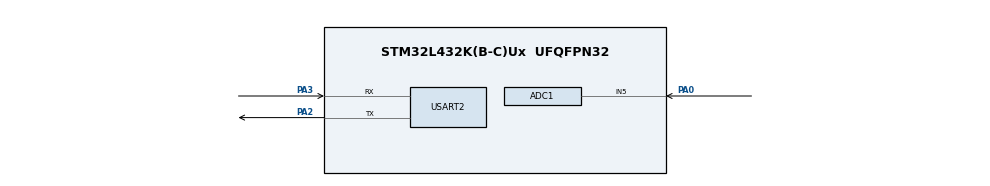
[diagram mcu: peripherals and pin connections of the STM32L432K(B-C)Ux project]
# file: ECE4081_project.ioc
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ADC1.Channel-0\#ChannelRegularConversion=ADC_CHANNEL_5
ADC1.NbrOfConversionFlag=1
ADC1.OffsetNumber-0\#ChannelRegularConversion=ADC_OFFSET_NONE
ADC1.Rank-0\#ChannelRegularConversion=1
ADC1.SamplingTime-0\#ChannelRegularConversion=ADC_SAMPLETIME_2CYCLES_5
ADC1.master=1
Mcu.Family=STM32L4
Mcu.Name=STM32L432K(B-C)Ux
Mcu.Package=UFQFPN32
NVIC.PriorityGroup=NVIC_PRIORITYGROUP_4
NVIC.TIM6_DAC_IRQn=true\:0\:0\:false\:false\:true\:true\:true\:true
PA0.Signal=ADCx_IN5
PA13\ (JTMS-SWDIO).Mode=Serial_Wire
PA13\ (JTMS-SWDIO).Signal=SYS_JTMS-SWDIO
PA14\ (JTCK-SWCLK).Mode=Serial_Wire
PA14\ (JTCK-SWCLK).Signal=SYS_JTCK-SWCLK
PA2.Mode=Asynchronous
PA2.Signal=USART2_TX
PA3.Mode=Asynchronous
PA3.Signal=USART2_RX
ProjectManager.HeapSize=0x200
ProjectManager.StackSize=0x400
ProjectManager.TargetToolchain=STM32CubeIDE
RCC.ADCFreq_Value=32000000
RCC.HSE_VALUE=8000000
RCC.HSI48_VALUE=48000000
RCC.HSI_VALUE=16000000
RCC.LSE_VALUE=32768
RCC.MSI_VALUE=4000000
RCC.PLLSAI1N=16
RCC.USBFreq_Value=32000000
RCC.VCOOutputFreq_Value=32000000
SH.ADCx_IN5.0=ADC1_IN5,IN5-Single-Ended
TIM6.Period=999
TIM6.Prescaler=3
USART2.VirtualMode-Asynchronous=VM_ASYNC
VP_TIM6_VS_ClockSourceINT.Mode=Enable_Timer
board=custom

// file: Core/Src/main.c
/* USER CODE BEGIN Header */
/**
  ******************************************************************************
  * @file           : main.c
  * @brief          : Main program body
  ******************************************************************************
  * @attention
  *
  * Copyright (c) 2026 STMicroelectronics.
  * All rights reserved.
  *
  * This software is licensed under terms that can be found in the LICENSE file
  * in the root directory of this software component.
  * If no LICENSE file comes with this software, it is provided AS-IS.
  *
  ******************************************************************************
  */
/* USER CODE END Header */
#include "main.h"
#include <stdio.h>

ADC_HandleTypeDef hadc1;

TIM_HandleTypeDef htim6;

UART_HandleTypeDef huart2;

/* USER CODE BEGIN PV */
#define SAMPLE_BUFFER_SIZE 256

volatile uint16_t sample_buffer[SAMPLE_BUFFER_SIZE];

volatile uint16_t write_index = 0;
volatile uint16_t read_index = 0;

volatile uint32_t dropped_samples = 0;

char msg[32];
/* USER CODE END PV */

void SystemClock_Config(void);
static void MX_GPIO_Init(void);
static void MX_ADC1_Init(void);
static void MX_USART2_UART_Init(void);
static void MX_TIM6_Init(void);

int main(void)
{

  /* MCU Configuration--------------------------------------------------------*/

  /* Reset of all peripherals, Initializes the Flash interface and the Systick. */
  HAL_Init();

  /* Configure the system clock */
  SystemClock_Config();

  /* Initialize all configured peripherals */
  MX_GPIO_Init();
  MX_ADC1_Init();
  MX_USART2_UART_Init();
  MX_TIM6_Init();
  /* USER CODE BEGIN 2 */
  HAL_ADCEx_Calibration_Start(
      &hadc1,
      ADC_SINGLE_ENDED
  );

  HAL_TIM_Base_Start_IT(
      &htim6
  );
  /* USER CODE END 2 */

  /* Infinite loop */
  while (1)
  {
	  if (read_index != write_index)
	      {
	          uint16_t adc_value =
	              sample_buffer[read_index];

	          read_index =
	              (read_index + 1)
	              % SAMPLE_BUFFER_SIZE;

	          int len = sprintf(
	              msg,
	              "%u\r\n",
	              adc_value
	          );

	          HAL_UART_Transmit(
	              &huart2,
	              (uint8_t *)msg,
	              len,
	              10
	          );
	      }
  }
}

void SystemClock_Config(void)
{
  RCC_OscInitTypeDef RCC_OscInitStruct = {0};
  RCC_ClkInitTypeDef RCC_ClkInitStruct = {0};

  /** Configure the main internal regulator output voltage
  */
  if (HAL_PWREx_ControlVoltageScaling(PWR_REGULATOR_VOLTAGE_SCALE1) != HAL_OK)
  {
    Error_Handler();
  }

  /** Initializes the RCC Oscillators according to the specified parameters
  * in the RCC_OscInitTypeDef structure.
  */
  RCC_OscInitStruct.OscillatorType = RCC_OSCILLATORTYPE_MSI;
  RCC_OscInitStruct.MSIState = RCC_MSI_ON;
  RCC_OscInitStruct.MSICalibrationValue = 0;
  RCC_OscInitStruct.MSIClockRange = RCC_MSIRANGE_6;
  RCC_OscInitStruct.PLL.PLLState = RCC_PLL_NONE;
  if (HAL_RCC_OscConfig(&RCC_OscInitStruct) != HAL_OK)
  {
    Error_Handler();
  }

  /** Initializes the CPU, AHB and APB buses clocks
  */
  RCC_ClkInitStruct.ClockType = RCC_CLOCKTYPE_HCLK|RCC_CLOCKTYPE_SYSCLK
                              |RCC_CLOCKTYPE_PCLK1|RCC_CLOCKTYPE_PCLK2;
  RCC_ClkInitStruct.SYSCLKSource = RCC_SYSCLKSOURCE_MSI;
  RCC_ClkInitStruct.AHBCLKDivider = RCC_SYSCLK_DIV1;
  RCC_ClkInitStruct.APB1CLKDivider = RCC_HCLK_DIV1;
  RCC_ClkInitStruct.APB2CLKDivider = RCC_HCLK_DIV1;

  if (HAL_RCC_ClockConfig(&RCC_ClkInitStruct, FLASH_LATENCY_0) != HAL_OK)
  {
    Error_Handler();
  }
}

static void MX_ADC1_Init(void)
{

  ADC_ChannelConfTypeDef sConfig = {0};

  /** Common config
  */
  hadc1.Instance = ADC1;
  hadc1.Init.ClockPrescaler = ADC_CLOCK_ASYNC_DIV1;
  hadc1.Init.Resolution = ADC_RESOLUTION_12B;
  hadc1.Init.DataAlign = ADC_DATAALIGN_RIGHT;
  hadc1.Init.ScanConvMode = ADC_SCAN_DISABLE;
  hadc1.Init.EOCSelection = ADC_EOC_SINGLE_CONV;
  hadc1.Init.LowPowerAutoWait = DISABLE;
  hadc1.Init.ContinuousConvMode = DISABLE;
  hadc1.Init.NbrOfConversion = 1;
  hadc1.Init.DiscontinuousConvMode = DISABLE;
  hadc1.Init.ExternalTrigConv = ADC_SOFTWARE_START;
  hadc1.Init.ExternalTrigConvEdge = ADC_EXTERNALTRIGCONVEDGE_NONE;
  hadc1.Init.DMAContinuousRequests = DISABLE;
  hadc1.Init.Overrun = ADC_OVR_DATA_PRESERVED;
  hadc1.Init.OversamplingMode = DISABLE;
  if (HAL_ADC_Init(&hadc1) != HAL_OK)
  {
    Error_Handler();
  }

  /** Configure Regular Channel
  */
  sConfig.Channel = ADC_CHANNEL_5;
  sConfig.Rank = ADC_REGULAR_RANK_1;
  sConfig.SamplingTime = ADC_SAMPLETIME_2CYCLES_5;
  sConfig.SingleDiff = ADC_SINGLE_ENDED;
  sConfig.OffsetNumber = ADC_OFFSET_NONE;
  sConfig.Offset = 0;
  if (HAL_ADC_ConfigChannel(&hadc1, &sConfig) != HAL_OK)
  {
    Error_Handler();
  }

}

static void MX_TIM6_Init(void)
{

  TIM_MasterConfigTypeDef sMasterConfig = {0};

  htim6.Instance = TIM6;
  htim6.Init.Prescaler = 3;
  htim6.Init.CounterMode = TIM_COUNTERMODE_UP;
  htim6.Init.Period = 999;
  htim6.Init.AutoReloadPreload = TIM_AUTORELOAD_PRELOAD_DISABLE;
  if (HAL_TIM_Base_Init(&htim6) != HAL_OK)
  {
    Error_Handler();
  }
  sMasterConfig.MasterOutputTrigger = TIM_TRGO_RESET;
  sMasterConfig.MasterSlaveMode = TIM_MASTERSLAVEMODE_DISABLE;
  if (HAL_TIMEx_MasterConfigSynchronization(&htim6, &sMasterConfig) != HAL_OK)
  {
    Error_Handler();
  }

}

static void MX_USART2_UART_Init(void)
{

  huart2.Instance = USART2;
  huart2.Init.BaudRate = 115200;
  huart2.Init.WordLength = UART_WORDLENGTH_8B;
  huart2.Init.StopBits = UART_STOPBITS_1;
  huart2.Init.Parity = UART_PARITY_NONE;
  huart2.Init.Mode = UART_MODE_TX_RX;
  huart2.Init.HwFlowCtl = UART_HWCONTROL_NONE;
  huart2.Init.OverSampling = UART_OVERSAMPLING_16;
  huart2.Init.OneBitSampling = UART_ONE_BIT_SAMPLE_DISABLE;
  huart2.AdvancedInit.AdvFeatureInit = UART_ADVFEATURE_NO_INIT;
  if (HAL_UART_Init(&huart2) != HAL_OK)
  {
    Error_Handler();
  }

}

static void MX_GPIO_Init(void)
{

  /* GPIO Ports Clock Enable */
  __HAL_RCC_GPIOA_CLK_ENABLE();

}

/* USER CODE BEGIN 4 */
void HAL_TIM_PeriodElapsedCallback(
    TIM_HandleTypeDef *htim
)
{
    if (htim->Instance == TIM6)
    {
        HAL_ADC_Start(&hadc1);

        if (
            HAL_ADC_PollForConversion(
                &hadc1,
                1
            ) == HAL_OK
        )
        {
            uint16_t adc_value =
                (uint16_t)
                HAL_ADC_GetValue(&hadc1);

            uint16_t next_index =
                (write_index + 1)
                % SAMPLE_BUFFER_SIZE;

            if (next_index != read_index)
            {
                sample_buffer[
                    write_index
                ] = adc_value;

                write_index =
                    next_index;
            }
            else
            {
                dropped_samples++;
            }
        }

        HAL_ADC_Stop(&hadc1);
    }
}
/* USER CODE END 4 */

void Error_Handler(void)
{
  __disable_irq();
  while (1)
  {
  }
}
